# DECODER0_PVDEC_ENTROPY register map
Vendor: Texas Instruments
Peripheral module from a debugger description file (folder J7ES).
Registers are 32-bit, read-write, reset 0x0 unless marked. A register's access mark holds for its fields unless they carry their own. Offsets are as the file gives them; lines under a group give offsets from that group; [hi:lo] are bit positions; {n}, {i} and the like mark numbered series; 'fields as' and 'values as' point back to an identical list; <NAME> marks a mode.

## DECODER0_PVDEC_ENTROPY
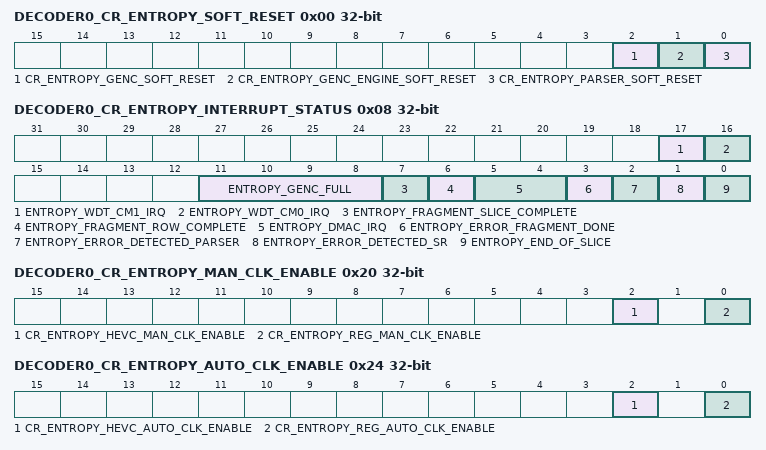
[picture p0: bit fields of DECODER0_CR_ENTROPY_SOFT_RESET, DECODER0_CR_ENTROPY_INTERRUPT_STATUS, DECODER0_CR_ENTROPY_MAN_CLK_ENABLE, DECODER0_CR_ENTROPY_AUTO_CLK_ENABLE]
0x00 DECODER0_CR_ENTROPY_SOFT_RESET
  [2] CR_ENTROPY_GENC_SOFT_RESET — Writing '1' to this bit resets the genc_enc [GENC] module of PVDEC_ENTROPY pipe.
  [1] CR_ENTROPY_GENC_ENGINE_SOFT_RESET — Writing '1' to this bit resets the arithmetic encode engine in the genc_enc [GENC] module of PVDEC_ENTROPY pipe.
  [0] CR_ENTROPY_PARSER_SOFT_RESET — Writing '1' to this bit resets the parser and encap modules of PVDEC_ENTROPY pipe.
0x08 DECODER0_CR_ENTROPY_INTERRUPT_STATUS
  [17] ENTROPY_WDT_CM1_IRQ — CompareMatch1 condition encountered by Entropy pipe Watch Dog Timer.
  [16] ENTROPY_WDT_CM0_IRQ — CompareMatch0 condition encountered by Entropy pipe Watch Dog Timer.
  [11:8] ENTROPY_GENC_FULL — For each of the four GENC buffers, this flag is set if the GENC buffer becomes full.
  [7] ENTROPY_FRAGMENT_SLICE_COMPLETE — Pulse generated when 'END_OF_SLICE' generated by parser has been processed by fragment pointer logic.
  [6] ENTROPY_FRAGMENT_ROW_COMPLETE — Pulse generated after every four complete macroblock rows of a picture have been written to the GENC fragment pointer table.
  [5:4] ENTROPY_DMAC_IRQ — Interrupt from the DMAC feeding the shift register.
  [3] ENTROPY_ERROR_FRAGMENT_DONE — An error which was detected in shift register or parser has propogated through to the fragment pointer logic and it is now safe to change slice level registers.
  [2] ENTROPY_ERROR_DETECTED_PARSER — Error detected by entropy bit stream parser.
  [1] ENTROPY_ERROR_DETECTED_SR — Error detected in the bit stream by shift register.
  [0] ENTROPY_END_OF_SLICE — End of slice status bit for the Entrpy parser.
0x0C DECODER0_CR_ENTROPY_INTERRUPT_CLEAR
  [31:0] ENTROPY_IRQ_CLEAR — The value read from the ENTROPY_INTERRUPT_STATUS register is based on 'input source' ORed with 'rising edge detection' logic.
0x10 DECODER0_CR_ENTROPY_HOST_INTERRUPT_ENABLE
  [31:0] CR_HOST_IRQ_ENABLE — Enables interrupts which will become a HOST_ENTROPY_PIPE_IRQ in the PVDEC registers.
0x14 DECODER0_CR_ENTROPY_PROC1_INTERRUPT_ENABLE
  [31:0] CR_PROC1_IRQ_ENABLE — Enables interrupts which will become a PROC1_ENTROPY_PIPE_IRQ in the PVDEC registers.
0x18 DECODER0_CR_ENTROPY_PROC2_INTERRUPT_ENABLE
  [31:0] CR_PROC2_IRQ_ENABLE — Enables interrupts which will become a PROC2_ENTROPY_PIPE_IRQ in the PVDEC registers.
0x20 DECODER0_CR_ENTROPY_MAN_CLK_ENABLE
  [2] CR_ENTROPY_HEVC_MAN_CLK_ENABLE — Controls the clock for the HEVC Decode pipeline [if this bit is set, clock is active, and AUTO_CLK_ENABLE is ignored]
  [0] CR_ENTROPY_REG_MAN_CLK_ENABLE — Controls the clock for the entropy pipe registers [if this bit is set, clock is active, and AUTO_CLK_ENABLE is ignored]
0x24 DECODER0_CR_ENTROPY_AUTO_CLK_ENABLE
  [2] CR_ENTROPY_HEVC_AUTO_CLK_ENABLE — Controls automatic clock gating for the HEVC pipeline logic [if MAN_CLK_ENABLE is clear and AUTO_CLK_ENABLE is set, clock will stop if HEVC Pipeline is idle]
  [0] CR_ENTROPY_REG_AUTO_CLK_ENABLE — Controls automatic clock gating for the Entropy Pipe registers [if MAN_CLK_ENABLE is clear and AUTO_CLK_ENABLE is set, clock will stop if Entropy Pipe register access is idle]
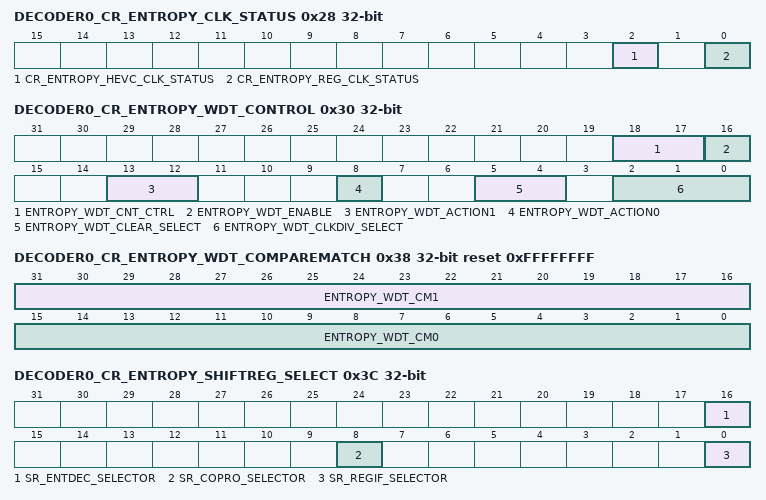
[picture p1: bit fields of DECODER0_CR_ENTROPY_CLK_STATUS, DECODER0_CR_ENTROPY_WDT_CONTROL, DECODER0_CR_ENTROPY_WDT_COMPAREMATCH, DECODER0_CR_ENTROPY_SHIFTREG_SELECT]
0x28 DECODER0_CR_ENTROPY_CLK_STATUS ro
  [2] CR_ENTROPY_HEVC_CLK_STATUS — Indicates if the clock is enabled to the HEVC Decode pipeline
  [0] CR_ENTROPY_REG_CLK_STATUS — Indicates if the clock is enabled to the Entropy pipe registers
0x30 DECODER0_CR_ENTROPY_WDT_CONTROL
  [18:17] ENTROPY_WDT_CNT_CTRL — The increment of ENTROPY_WDT counter can be controlled depending on the settings below.
  [16] ENTROPY_WDT_ENABLE — Front-end Watch Dog Timer enable
  [13:12] ENTROPY_WDT_ACTION1 — Watch Dog Timer action upon WDT_COMPAREMATCH1
  [8] ENTROPY_WDT_ACTION0 — Watch Dog Timer action upon WDT_COMPAREMATCH0.
  [5:4] ENTROPY_WDT_CLEAR_SELECT — Watch Dog Timer clear select
  [2:0] ENTROPY_WDT_CLKDIV_SELECT — Watch Dog Timer clock select
0x34 DECODER0_CR_ENTROPY_WDTIMER
  [15:0] ENTROPY_WDT_COUNTER — Watch Dog Timer counter value.
0x38 DECODER0_CR_ENTROPY_WDT_COMPAREMATCH reset 0xFFFFFFFF
  [31:16] ENTROPY_WDT_CM1 — Watch Dog Timer compare-match register.
  [15:0] ENTROPY_WDT_CM0 — Watch Dog Timer compare-match register.
0x3C DECODER0_CR_ENTROPY_SHIFTREG_SELECT
  [16] SR_ENTDEC_SELECTOR — If the entropy core is configured to support two shift registers, this field is used to select the instance of the Shift Register that can be accessed by the Entropy Decoder
  [8] SR_COPRO_SELECTOR — If the entropy core is configured to support two shift registers, this field is used to select the instance of the Shift Register that can be accessed via the MTX Co-processor Port
  [0] SR_REGIF_SELECTOR — If the entropy core is configured to support two shift registers, this field is used to select the instance of the Shift Register that can be accessed via the register interface
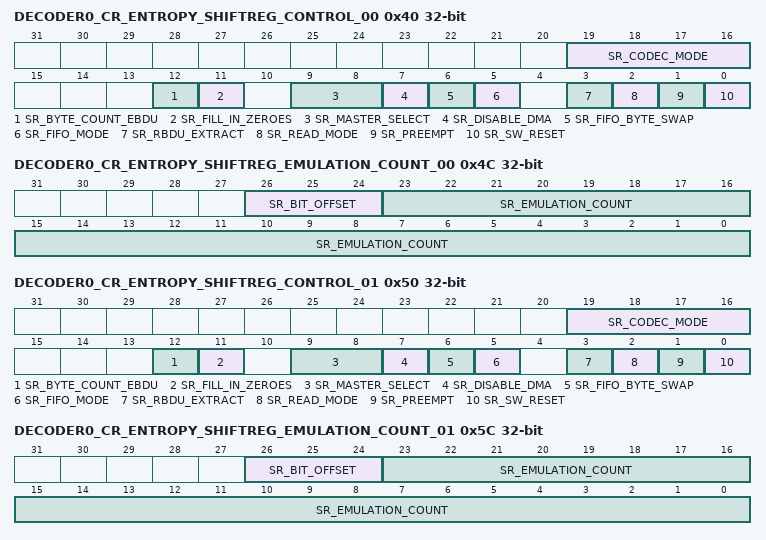
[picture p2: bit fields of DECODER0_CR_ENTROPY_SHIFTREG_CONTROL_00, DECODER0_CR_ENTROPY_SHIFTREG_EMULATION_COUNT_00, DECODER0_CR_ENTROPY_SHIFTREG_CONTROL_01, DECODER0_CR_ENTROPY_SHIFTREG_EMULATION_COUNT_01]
0x40 DECODER0_CR_ENTROPY_SHIFTREG_CONTROL_00
  [19:16] SR_CODEC_MODE — Codec mode which the shift register works in [affects emulation prevention detection and other operations fro JPEG].
  [12] SR_BYTE_COUNT_EBDU — If SR_RBDU_EXTRACT is set, then this field affects how byte count works
  [11] SR_FILL_IN_ZEROES — If SR_READ_MODE = 0 and byte count is set, then fifo will be filled in zeroes when byte count becomes zero
  [9:8] SR_MASTER_SELECT — Specifies which requestor is the master of this Shift Register channel
  [7] SR_DISABLE_DMA — Controls the assertion of DREQ from ShiftReg to DMAC
  [6] SR_FIFO_BYTE_SWAP — Controls whether the
  [5] SR_FIFO_MODE — Controls whether ShiftReg FIFO is used as a
  [3] SR_RBDU_EXTRACT — Controls 'raw bit stream data unit' extraction
  [2] SR_READ_MODE — Controls whether Start Code Prefixes are detected or whether byte_count is used to control the amount of data read through the ShiftReg
  [1] SR_PREEMPT — Allows pre-emption of any pending MTX ShiftReg Co-processor read
  [0] SR_SW_RESET — Shift Register software reset
0x44 DECODER0_CR_ENTROPY_SHIFTREG_BYTE_COUNT_00 reset 0xFFFFFF — Used to control the amount of bit stream data that can be read through the Shift RegisterNOTE: Writing to this register clears the End-of-Data flag and allows more bit stream data to be read through the Shift Register
  [31:0] SR_BYTE_COUNT — Count of bytes that should be processed before returning control to MTX.
0x48 DECODER0_CR_ENTROPY_SHIFTREG_STREAMIN_00
  [7:0] SR_STREAMIN — Input for the compressed bit stream
0x4C DECODER0_CR_ENTROPY_SHIFTREG_EMULATION_COUNT_00 ro
  [26:24] SR_BIT_OFFSET — In byte count mode, SR_BYTE_COUNT*8 + SR_BIT_OFFSET indicates the number of bits left [this is mainly for firmware to know the bit offset at the end of a slice header].
  [23:0] SR_EMULATION_COUNT — If SR_RBDU_EXTRACT is set, this field indicates the number of emulation prevention bytes which have been removed [where the count is aligned to the actual bits consumed from the shift register]
0x50 DECODER0_CR_ENTROPY_SHIFTREG_CONTROL_01
  fields as DECODER0_CR_ENTROPY_SHIFTREG_CONTROL_00
0x54 DECODER0_CR_ENTROPY_SHIFTREG_BYTE_COUNT_01 reset 0xFFFFFF — Used to control the amount of bit stream data that can be read through the Shift RegisterNOTE: Writing to this register clears the End-of-Data flag and allows more bit stream data to be read through the Shift Register
  fields as DECODER0_CR_ENTROPY_SHIFTREG_BYTE_COUNT_00
0x58 DECODER0_CR_ENTROPY_SHIFTREG_STREAMIN_01
  [7:0] SR_STREAMIN — Input for the compressed bit stream
0x5C DECODER0_CR_ENTROPY_SHIFTREG_EMULATION_COUNT_01 ro
  fields as DECODER0_CR_ENTROPY_SHIFTREG_EMULATION_COUNT_00
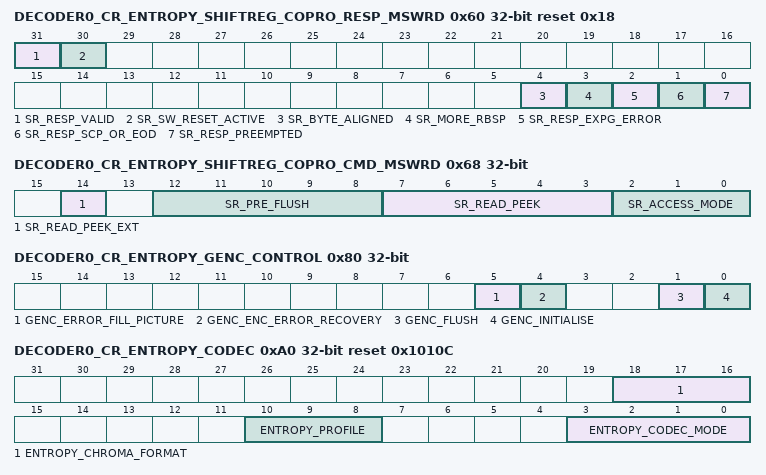
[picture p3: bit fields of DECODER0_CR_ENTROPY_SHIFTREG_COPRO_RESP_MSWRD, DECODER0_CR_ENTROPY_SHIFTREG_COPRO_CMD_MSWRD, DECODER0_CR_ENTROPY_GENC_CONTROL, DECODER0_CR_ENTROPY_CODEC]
0x60 DECODER0_CR_ENTROPY_SHIFTREG_COPRO_RESP_MSWRD reset 0x18 — Provides direct access to the most significant 32-bits of the Shift Register co-processor response port.
  [31] SR_RESP_VALID — Indicates the Shift Register response contains valid data.
  [30] SR_SW_RESET_ACTIVE — Indicates whether the Shift Register is being reset
  [4] SR_BYTE_ALIGNED — Indicates whether the next bit in the Shift Register is byte aligned
  [3] SR_MORE_RBSP — Use to signal more raw bit stream data
  [2] SR_RESP_EXPG_ERROR
  [1] SR_RESP_SCP_OR_EOD
  [0] SR_RESP_PREEMPTED
0x64 DECODER0_CR_ENTROPY_SHIFTREG_COPRO_RESP_LSWRD — Provides direct access to the least significant 32-bits of the Shift Register co-processor response port.
  [31:0] SR_RESP_VALUE — Requested bits or signed/unsigned Exp-Goulomb value
0x68 DECODER0_CR_ENTROPY_SHIFTREG_COPRO_CMD_MSWRD — Provides direct access to the most significant 32-bits of the Shift Register co-processor command port.
  [14] SR_READ_PEEK_EXT — Read Peek Extended.
  [12:8] SR_PRE_FLUSH — Discard or flush bits from the bit stream before read/peek/skip - 0 to 31
  [7:3] SR_READ_PEEK — The number of bits to read/peek - 0 to
  [2:0] SR_ACCESS_MODE — The access mode:
0x80 DECODER0_CR_ENTROPY_GENC_CONTROL
  [5] GENC_ERROR_FILL_PICTURE — If an error occurs in a slice, and there are no more slices to process in this picture, s/w can write 1 to this bit to trigger the fragment pointer logic to fill-in bad fragments from the last good fragment processed to the end of the picture.
  [4] GENC_ENC_ERROR_RECOVERY — When a lock-up is detected at the front-end, s/w must write 1 to this bit before resetting the front-end modules.
  [1] GENC_FLUSH — Writing '1' to this bit flushes the GENC/encoder's remaining bit stream with [if necessary] some extra bits so that the encoded bit stream is aligned to the memory burst size.
  [0] GENC_INITIALISE — Writing 1 to this bit initialises the GENC encoder contexts to the value programmed into GENC_CONTEXT registers.
0x90 DECODER0_CR_ENTROPY_SLICE_PARAMETER_ADDRESS
  [31:6] SLICE_PARAMETER_ADDRESS — The address of slice parameter structure, aligned to a multiple of 64 bytes, where the address will be stored in each GENC fragment within the slice, and then used by the Pixel processing pipes to read the slice parameter structure to be used by the pixel processing pipeline
0x94 DECODER0_CR_ENTROPY_SLICE_PARAMETER_SIZE
  [3:0] SLICE_PARAMETER_SIZE — The size of slice parameter structure, where the size in bytes is [SLICE_PARAMETER_SIZE+1]*64.
0x98 DECODER0_CR_GENC_FRAGMENT_BASE_ADDRESS
  [31:6] FRAGMENT_BASE_ADDRESS — The base address of the GENC fragment pointer table
0xA0 DECODER0_CR_ENTROPY_CODEC reset 0x1010C
  [18:16] ENTROPY_CHROMA_FORMAT — Defines the chroma format;-
  [10:8] ENTROPY_PROFILE — Defines profile for the front-end for the selected codec mode [definition based on ENTROPY_CODEC_MODE]
  [3:0] ENTROPY_CODEC_MODE — 0xC : HEVC
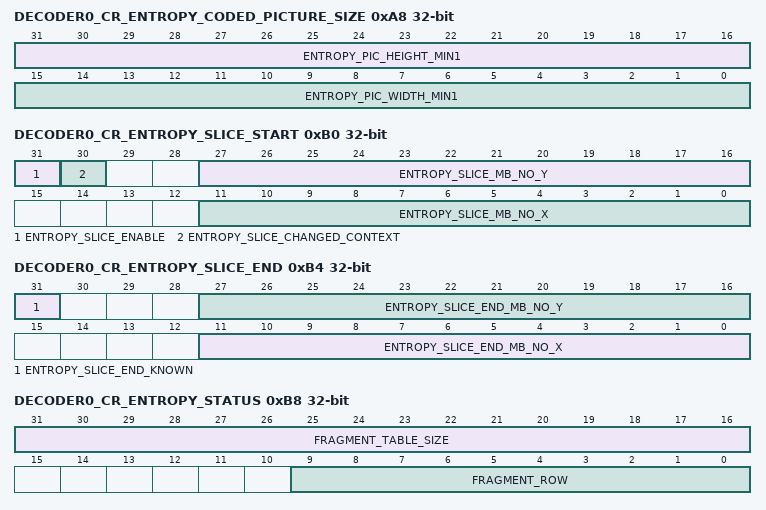
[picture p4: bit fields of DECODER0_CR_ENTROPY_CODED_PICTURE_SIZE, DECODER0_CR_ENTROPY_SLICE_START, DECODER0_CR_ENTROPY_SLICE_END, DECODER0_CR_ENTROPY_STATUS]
0xA8 DECODER0_CR_ENTROPY_CODED_PICTURE_SIZE
  [31:16] ENTROPY_PIC_HEIGHT_MIN1 — Defines 1 less than picture height in luma samples
  [15:0] ENTROPY_PIC_WIDTH_MIN1 — Defines 1 less than picture width in luma samples
0xB0 DECODER0_CR_ENTROPY_SLICE_START
  [31] ENTROPY_SLICE_ENABLE — Writing 1 to this field starts the entropy decode of the slice.
  [30] ENTROPY_SLICE_CHANGED_CONTEXT — When writing 1 to ENTROPY_SLICE_ENABLE to start the entropy decode of the slice, if this flag is also set to 1 it indicates software has just switched context back to this picture [i.e.
  [27:16] ENTROPY_SLICE_MB_NO_Y — The vertical offset of the first 16x16 block in the slice [counting from 0] [For HEVC CTU sizes larger than 16x16 this is the co-ordinate of the top left 16x16 block within the CTU.
  [11:0] ENTROPY_SLICE_MB_NO_X — The horizontal offset of the first 16x16 block in the slice [counting from 0] [For HEVC CTU sizes larger than 16x16 this is the co-ordinate of the top left 16x16 block within the CTU.
0xB4 DECODER0_CR_ENTROPY_SLICE_END
  [31] ENTROPY_SLICE_END_KNOWN — If this flag is low, the hardware may only be able to detect a slice overrun if the last CTU in a piture isn't followed by an 'end_of_slice_segment_flag == 1'.
  [27:16] ENTROPY_SLICE_END_MB_NO_Y — The vertical offset of the last 16x16 block in the slice if it is known [counting from 0] [For HEVC CTU sizes larger than 16x16 this is the co-ordinate of the bottom right 16x16 block within the CTU]
  [11:0] ENTROPY_SLICE_END_MB_NO_X — The horizontal offset of the last 16x16 block in the slice if it is known [counting from 0] [For HEVC CTU sizes larger than 16x16 this is the co-ordinate of the bottom right 16x16 block within the CTU]
0xB8 DECODER0_CR_ENTROPY_STATUS
  [31:16] FRAGMENT_TABLE_SIZE — The number of allocated entries in the GENC fragment pointer table.
  [9:0] FRAGMENT_ROW — Indicates the last full row of a fragment pointer table entries have been written to memory, in multiples of 4 macroblock rows [e.g.
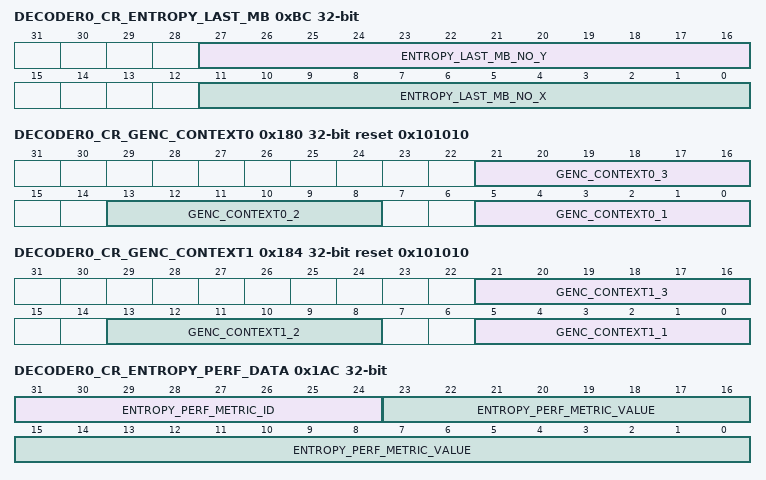
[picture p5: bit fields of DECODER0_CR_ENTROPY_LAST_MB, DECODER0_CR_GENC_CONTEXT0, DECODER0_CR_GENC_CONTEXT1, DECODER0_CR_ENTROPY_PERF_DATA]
0xBC DECODER0_CR_ENTROPY_LAST_MB
  [27:16] ENTROPY_LAST_MB_NO_Y — The vertical offset of the last 16x16 block processed [For HEVC CTU sizes larger than 16x16 this is the co-ordinate of the bottom right 16x16 block within the CTU].
  [11:0] ENTROPY_LAST_MB_NO_X — The horizontal offset of the last 16x16 block processed [For HEVC CTU sizes larger than 16x16 this is the co-ordinate of the bottom right 16x16 block within the CTU].
0xC0 DECODER0_CR_ENTROPY_PIPE_CONFIG ro
  [31:0] CR_ENTROPY_PIPE_CONFIG — This field indicates which CODECs are supported in an Entropy Pipe [where different pipes can be configured to support a different range of codecs].
0xD0 DECODER0_CR_MEM_SECURITY_ENTROPY_0
  [31:0] CR_MEM_SECURITY_ENTROPY_CTRL_0 — MEM_TAG_ID of entropy_pipe is compared to the corresponding bit position of the concatenated field [ENTROPY_1 &amp; ENTROPY_0] to determine whether to flag the Security or not
0xD4 DECODER0_CR_MEM_SECURITY_ENTROPY_1
  [31:0] CR_MEM_SECURITY_ENTROPY_CTRL_1 — Refer to MEM_SECURITY_ENTROPY_CTRL_0
{0x100+4i} DECODER0_CR_GENC_BUFFER_SIZE_{i:02} (i=0..3) — GENC Buffer Size, in multiple of 4kbytes, for each of the four GENC buffers
  [27:12] GENC_BUFFER_SIZE — GENC buffer size, in multiple of 4kbyte, where a value of zero is illegal [maximum buffer size is 256Mbyte-4kbyte]
{0x110+4i} DECODER0_CR_GENC_BUFFER_BASE_ADDRESS_{i:02} (i=0..3) — GENC Buffer Base Address, must be aligned to a multiple of 4kbytes, for each of the four GENC buffers
  [31:12] GENC_BASE_ADDRESS — GENC buffer base address, must be aligned to a multiple of 4kbyte
{0x120+4i} DECODER0_CR_GENC_BUFFER_WRITE_POINTER_{i:02} (i=0..3) — GENC Buffer Write Pointer for each of the four GENC buffers
  [27:4] GENC_WRITE_POINTER — GENC write pointer, offset relative to the base address which points to the next
{0x130+4i} DECODER0_CR_GENC_BUFFER_READ_POINTER_{i:02} (i=0..3) — GENC Buffer Read Pointer for each of the four GENC buffers
  [27:4] GENC_READ_POINTER — GENC read pointer, offset relative to the base address which points to the next
0x180 DECODER0_CR_GENC_CONTEXT0 reset 0x101010
  [21:16] GENC_CONTEXT0_3 — GENC initial context value for CU context with a value of 3
  [13:8] GENC_CONTEXT0_2 — GENC initial context value for CU context with a value of 2
  [5:0] GENC_CONTEXT0_1 — GENC initial context value for CU context with a value of 1
0x184 DECODER0_CR_GENC_CONTEXT1 reset 0x101010
  [21:16] GENC_CONTEXT1_3 — GENC initial context value for significance map context with a value of 3
  [13:8] GENC_CONTEXT1_2 — GENC initial context value for significance map context with a value of 2
  [5:0] GENC_CONTEXT1_1 — GENC initial context value for significance map context with a value of 1
0x190 DECODER0_CR_ENTROPY_FRAME_ID
  [31:0] ENTROPY_FRAME_ID — When bit-stream status parameters are output via a hardware interface, the contents of this register are also output to identify the stream and frame the parameters are from [which may be used to align the parameters to the corresponding commands from the back-end]
0x1A8 DECODER0_CR_ENTROPY_PERF_STATUS ro
  [0] ENTROPY_PERF_DATA_VALID — Indicates that there are valid performance metrics to be read out of the ENTROPY_PERF_DATA register.
0x1AC DECODER0_CR_ENTROPY_PERF_DATA — Contains the various performance metrics captured by the hardware. All metrics are presented in the order in which they complete, and are grouped by category.Reads from this register are destructive - the data at the front of the buffer will be consumed, and replaced with the next metric in chronological order.
  [31:24] ENTROPY_PERF_METRIC_ID — Contains the metric ID.
  [23:0] ENTROPY_PERF_METRIC_VALUE — The definition of the metric value is dependent on the metric ID.
0x1B8 DECODER0_CR_HEVC_PARSER_SIGNATURE ro — This is a signature of the symbol output interface of the HEVC Parser to Encap.
  [31:0] HEVC_PARSER_SIGNATURE — The signature for the output interface of the HEVC parser.
0x1BC DECODER0_CR_ENCAP_SIGNATURE ro — This is a signature of the syntax element interface output of Encap to GENC ENC.
  [31:0] ENCAP_SIGNATURE — The signature for the output interface of encap.
{0x1C0+4i} DECODER0_CR_GENC_BUFFER_SIGNATURE_{i:02} ro (i=0..3) — For each of the four GENC buffers, this is a signature of the data written to the buffer.
  [31:0] GENC_BUFFER_SIGNATURE — GENC buffer signature, of the 128-bit data words written to the GENC buffer.
0x1D0 DECODER0_CR_GENC_FRAGMENT_SIGNATURE ro — This is a signature of the 128-data words written to the GENC fragment pointer table.
  [31:0] GENC_FRAGMENT_SIGNATURE — GENC fragment signature, of the 128-bit data words written to the GENC fragment pointer table.
0x1D4 DECODER0_CR_GENC_FRAGMENT_READ_SIGNATURE ro — This is a signature of the 128-data words read from the GENC fragment pointer table.
  [31:0] GENC_FRAGMENT_READ_SIGNATURE — GENC fragment read signature, of the 128-bit data words read from the GENC fragment pointer table.
0x1D8 DECODER0_CR_GENC_FRAGMENT_WRADDR_SIGNATURE ro — This is a signature of the burst length and write address offset of writes to the GENC fragment pointer table.
  [31:0] GENC_FRAGMENT_WRADDR_SIGNATURE — GENC fragment write address offset signature, consisting of the burst length[2 bits] and write address offset[14bits] of writes to the GENC fragment pointer table.
0x1E0 DECODER0_CR_GENC_ENGINE_OUTPUT_SIGNATURE ro — This is a signature of the output of the arithmetic encode engine.
  [31:0] GENC_ENGINE_OUTPUT_SIGNATURE
0x1E4 DECODER0_CR_HEVC_PARAMS_SIGNATURE ro — This is a signature of the output of the hevc params interface.
  [31:0] HEVC_PARAMS_SIGNATURE — This is a signature of the output of the hevc params count interface.
0x1E8 DECODER0_CR_SR_SIGNATURE_00 — Contains the CRC signature for write data into the shift register FIFO
  [31:0] SR_SIGNATURE — Signature CRC for shift register input data to FIFO [a write to this register clears the signature]
0x1EC DECODER0_CR_SR_SIGNATURE_01 — Contains the CRC signature for write data into the shift register FIFO
  fields as DECODER0_CR_SR_SIGNATURE_00
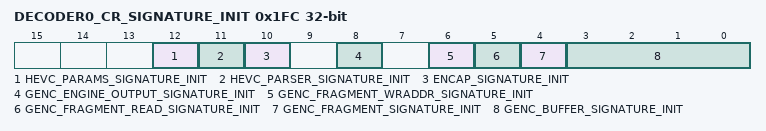
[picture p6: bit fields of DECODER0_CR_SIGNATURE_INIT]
0x1FC DECODER0_CR_SIGNATURE_INIT
  [12] HEVC_PARAMS_SIGNATURE_INIT — Writing a '1' to this field initialises the HEVC_PARAMS_SIGNATURE [writing '0' has no affect]
  [11] HEVC_PARSER_SIGNATURE_INIT — Writing a '1' to this field initialises the HEVC_PARSER_SIGNATURE [writing '0' has no affect]
  [10] ENCAP_SIGNATURE_INIT — Writing a '1' to this field initialises the ENCAP_SIGNATURE [writing '0' has no affect]
  [8] GENC_ENGINE_OUTPUT_SIGNATURE_INIT — Writing a '1' to this field initialises the GENC_ENGINE_OUTPUT_SIGNATURE [writing '0' has no affect]
  [6] GENC_FRAGMENT_WRADDR_SIGNATURE_INIT — Writing a '1' to this field initialises the GENC_FRAGMENT_WRADDR_SIGNATURE [writing '0' has no affect]
  [5] GENC_FRAGMENT_READ_SIGNATURE_INIT — Writing a '1' to this field initialises the GENC_FRAGMENT_READ_SIGNATURE [writing '0' has no affect]
  [4] GENC_FRAGMENT_SIGNATURE_INIT — Writing a '1' to this field initialises the GENC_FRAGMENT_SIGNATURE [writing '0' has no affect]
  [3:0] GENC_BUFFER_SIGNATURE_INIT — For each of the four GENC_BUFFER_SIGNATURE registers, writing a '1' to this field initialises the signature [writing '0' has no affect]
